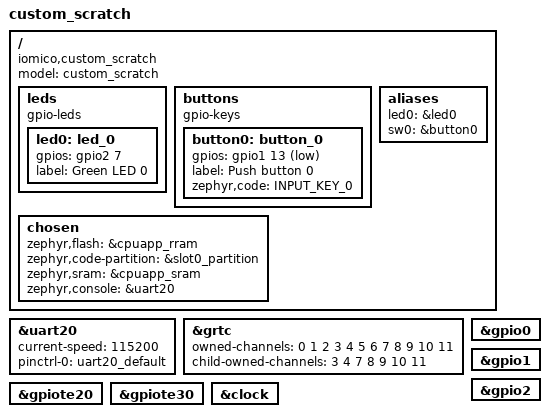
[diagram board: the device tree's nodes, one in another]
/*
 * Custom nRF54l15dk-compatible board from scratch
 */

/dts-v1/;

#include <nordic/nrf54l15_cpuapp.dtsi>
#include "custom_scratch-pinctrl.dtsi"

/ {
	model = "custom_scratch";
	compatible = "iomico,custom_scratch";

	leds {
		compatible = "gpio-leds";

		led0: led_0 {
			gpios = <&gpio2 7 GPIO_ACTIVE_HIGH>;
			label = "Green LED 0";
		};
	};

	buttons {
		compatible = "gpio-keys";

		button0: button_0 {
			gpios = <&gpio1 13 (GPIO_PULL_UP | GPIO_ACTIVE_LOW)>;
			label = "Push button 0";
			zephyr,code = <INPUT_KEY_0>;
		};
	};

	aliases {
		led0 = &led0;
		sw0 = &button0;
	};

	chosen {
		zephyr,flash = &cpuapp_rram;
		zephyr,code-partition = &slot0_partition;
		zephyr,sram = &cpuapp_sram;
		zephyr,console = &uart20;
	};
};

&uart20 {
	status = "okay";
	current-speed = <115200>;
	pinctrl-0 = <&uart20_default>;
	pinctrl-names = "default";
};

&grtc {
	owned-channels = <0 1 2 3 4 5 6 7 8 9 10 11>;
	/* Channels 7-11 reserved for Zero Latency IRQs, 3-4 for FLPR */
	child-owned-channels = <3 4 7 8 9 10 11>;
	status = "okay";
};

&gpio0 {
	status = "okay";
};

&gpio1 {
	status = "okay";
};

&gpio2 {
	status = "okay";
};

&gpiote20 {
	status = "okay";
};

&gpiote30 {
	status = "okay";
};

&clock {
	status = "okay";
};

#include <nordic/nrf54l15_partition.dtsi>
